# PIC32MZ2025DAS169 register map
Vendor: Microchip
Registers are 32-bit, read-write, reset 0x0 unless marked. A register's access mark holds for its fields unless they carry their own. Addresses are absolute, and some are shared; only a register's first bit layout is shown; [hi:lo] are bit positions.

## SPI3
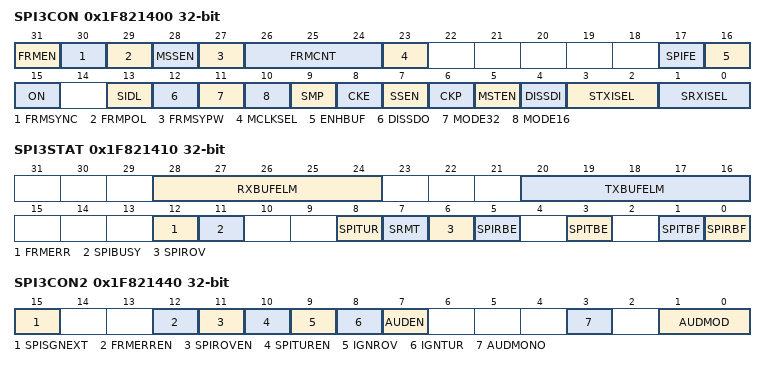
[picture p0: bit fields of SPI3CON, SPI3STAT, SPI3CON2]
0x1F821400 SPI3CON reset not defined — (power-on value 00000000x-----0000000000000x0000)
  [31] FRMEN, [30] FRMSYNC, [29] FRMPOL, [28] MSSEN, [27] FRMSYPW, [26:24] FRMCNT, [23] MCLKSEL, [17] SPIFE, [16] ENHBUF, [15] ON, [13] SIDL, [12] DISSDO, [11] MODE32, [10] MODE16, [9] SMP, [8] CKE, [7] SSEN, [6] CKP, [5] MSTEN, [4] DISSDI, [3:2] STXISEL, [1:0] SRXISEL
0x1F821410 SPI3STAT reset not defined — (power-on value ---00000---00000---x0--0000-0-00)
  [28:24] RXBUFELM ro, [20:16] TXBUFELM ro, [12] FRMERR, [11] SPIBUSY ro, [8] SPITUR ro, [7] SRMT ro, [6] SPIROV ro, [5] SPIRBE ro, [3] SPITBE ro, [1] SPITBF ro, [0] SPIRBF ro
0x1F821420 SPI3BUF reset not defined — (power-on value xxxxxxxxxxxxxxxxxxxxxxxxxxxxxxxx)
0x1F821430 SPI3BRG reset not defined — (power-on value -------------------xxxxxxxxxxxxx)
  [12:0] SPI3BRG
0x1F821440 SPI3CON2 reset not defined — (power-on value ----------------x--xxxxxx---x-xx)
  [15] SPISGNEXT, [12] FRMERREN, [11] SPIROVEN, [10] SPITUREN, [9] IGNROV, [8] IGNTUR, [7] AUDEN, [3] AUDMONO, [1:0] AUDMOD

## SPI4
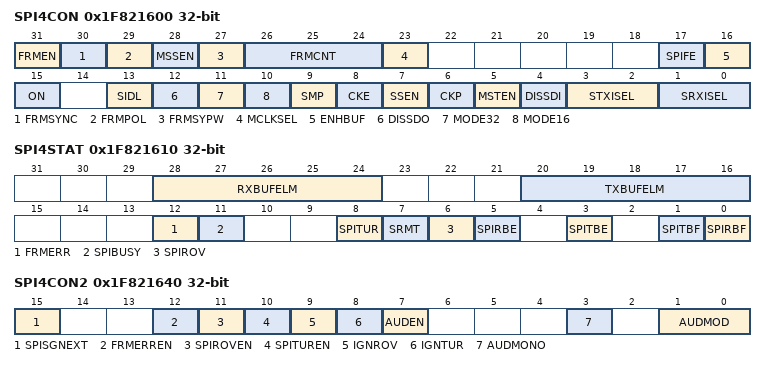
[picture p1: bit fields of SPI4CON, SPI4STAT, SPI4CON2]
0x1F821600 SPI4CON reset not defined — (power-on value 00000000x-----0000000000000x0000)
  [31] FRMEN, [30] FRMSYNC, [29] FRMPOL, [28] MSSEN, [27] FRMSYPW, [26:24] FRMCNT, [23] MCLKSEL, [17] SPIFE, [16] ENHBUF, [15] ON, [13] SIDL, [12] DISSDO, [11] MODE32, [10] MODE16, [9] SMP, [8] CKE, [7] SSEN, [6] CKP, [5] MSTEN, [4] DISSDI, [3:2] STXISEL, [1:0] SRXISEL
0x1F821610 SPI4STAT reset not defined — (power-on value ---00000---00000---x0--0000-0-00)
  [28:24] RXBUFELM ro, [20:16] TXBUFELM ro, [12] FRMERR, [11] SPIBUSY ro, [8] SPITUR ro, [7] SRMT ro, [6] SPIROV ro, [5] SPIRBE ro, [3] SPITBE ro, [1] SPITBF ro, [0] SPIRBF ro
0x1F821620 SPI4BUF reset not defined — (power-on value xxxxxxxxxxxxxxxxxxxxxxxxxxxxxxxx)
0x1F821630 SPI4BRG reset not defined — (power-on value -------------------xxxxxxxxxxxxx)
  [12:0] SPI4BRG
0x1F821640 SPI4CON2 reset not defined — (power-on value ----------------x--xxxxxx---x-xx)
  [15] SPISGNEXT, [12] FRMERREN, [11] SPIROVEN, [10] SPITUREN, [9] IGNROV, [8] IGNTUR, [7] AUDEN, [3] AUDMONO, [1:0] AUDMOD

## SPI5
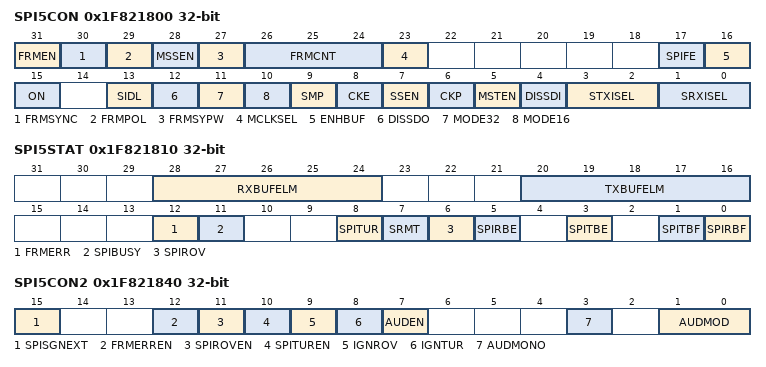
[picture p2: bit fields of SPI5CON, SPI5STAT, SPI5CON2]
0x1F821800 SPI5CON reset not defined — (power-on value 00000000x-----0000000000000x0000)
  [31] FRMEN, [30] FRMSYNC, [29] FRMPOL, [28] MSSEN, [27] FRMSYPW, [26:24] FRMCNT, [23] MCLKSEL, [17] SPIFE, [16] ENHBUF, [15] ON, [13] SIDL, [12] DISSDO, [11] MODE32, [10] MODE16, [9] SMP, [8] CKE, [7] SSEN, [6] CKP, [5] MSTEN, [4] DISSDI, [3:2] STXISEL, [1:0] SRXISEL
0x1F821810 SPI5STAT reset not defined — (power-on value ---00000---00000---x0--0000-0-00)
  [28:24] RXBUFELM ro, [20:16] TXBUFELM ro, [12] FRMERR, [11] SPIBUSY ro, [8] SPITUR ro, [7] SRMT ro, [6] SPIROV ro, [5] SPIRBE ro, [3] SPITBE ro, [1] SPITBF ro, [0] SPIRBF ro
0x1F821820 SPI5BUF reset not defined — (power-on value xxxxxxxxxxxxxxxxxxxxxxxxxxxxxxxx)
0x1F821830 SPI5BRG reset not defined — (power-on value -------------------xxxxxxxxxxxxx)
  [12:0] SPI5BRG
0x1F821840 SPI5CON2 reset not defined — (power-on value ----------------x--xxxxxx---x-xx)
  [15] SPISGNEXT, [12] FRMERREN, [11] SPIROVEN, [10] SPITUREN, [9] IGNROV, [8] IGNTUR, [7] AUDEN, [3] AUDMONO, [1:0] AUDMOD

## SPI6
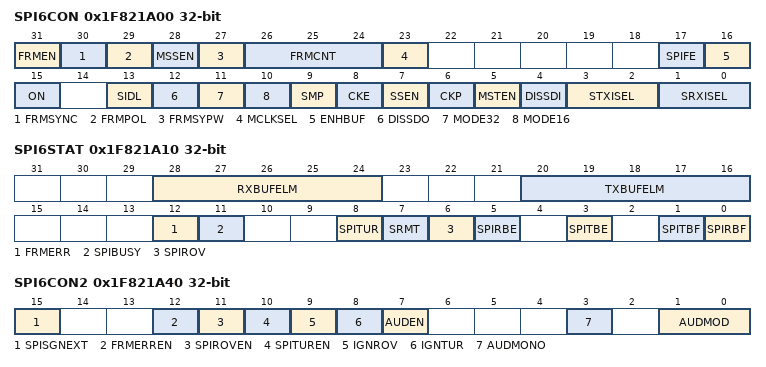
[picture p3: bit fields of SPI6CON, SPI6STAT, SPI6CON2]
0x1F821A00 SPI6CON reset not defined — (power-on value 00000000x-----0000000000000x0000)
  [31] FRMEN, [30] FRMSYNC, [29] FRMPOL, [28] MSSEN, [27] FRMSYPW, [26:24] FRMCNT, [23] MCLKSEL, [17] SPIFE, [16] ENHBUF, [15] ON, [13] SIDL, [12] DISSDO, [11] MODE32, [10] MODE16, [9] SMP, [8] CKE, [7] SSEN, [6] CKP, [5] MSTEN, [4] DISSDI, [3:2] STXISEL, [1:0] SRXISEL
0x1F821A10 SPI6STAT reset not defined — (power-on value ---00000---00000---x0--0000-0-00)
  [28:24] RXBUFELM ro, [20:16] TXBUFELM ro, [12] FRMERR, [11] SPIBUSY ro, [8] SPITUR ro, [7] SRMT ro, [6] SPIROV ro, [5] SPIRBE ro, [3] SPITBE ro, [1] SPITBF ro, [0] SPIRBF ro
0x1F821A20 SPI6BUF reset not defined — (power-on value xxxxxxxxxxxxxxxxxxxxxxxxxxxxxxxx)
0x1F821A30 SPI6BRG reset not defined — (power-on value -------------------xxxxxxxxxxxxx)
  [12:0] SPI6BRG
0x1F821A40 SPI6CON2 reset not defined — (power-on value ----------------x--xxxxxx---x-xx)
  [15] SPISGNEXT, [12] FRMERREN, [11] SPIROVEN, [10] SPITUREN, [9] IGNROV, [8] IGNTUR, [7] AUDEN, [3] AUDMONO, [1:0] AUDMOD
